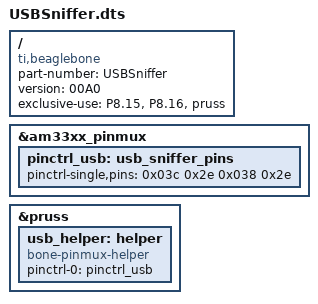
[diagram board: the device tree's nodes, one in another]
/*
 * Copyright (C) 2012 Texas Instruments Incorporated - http://www.ti.com/
 *
 * This program is free software; you can redistribute it and/or modify
 * it under the terms of the GNU General Public License version 2 as
 * published by the Free Software Foundation.
 */
/dts-v1/;
/plugin/;

/ {
	compatible = "ti,beaglebone", "ti,beaglebone-black";

	/* identification */
	part-number = "USBSniffer";
	version = "00A0";

        exclusive-use =
                /* the pin header uses */
                "P8.15",        /* pr1_pru0_pru_r31_15 */
                "P8.16",        /* pr1_pru0_pru_r31_14 */
		"pruss";		/* PRU */
		
	fragment@0 {
		target = <&am33xx_pinmux>;
		__overlay__ {
			pinctrl_usb: usb_sniffer_pins {
				pinctrl-single,pins = <
					0x03c 0x2e	/* P8_15 pr1_pru0_pru_r31_15 INPUT */
					0x038 0x2e	/* P8_11 pr1_pru0_pru_r31_14 INPUT */
				>;
			};
		};
	};

	fragment@1 {
		target = <&pruss>;
		__overlay__ {
			usb_helper: helper {
				compatible = "bone-pinmux-helper";
				pinctrl-names = "default";
				pinctrl-0 = <&pinctrl_usb>;
				status = "okay";
			};
		};
	};
};
